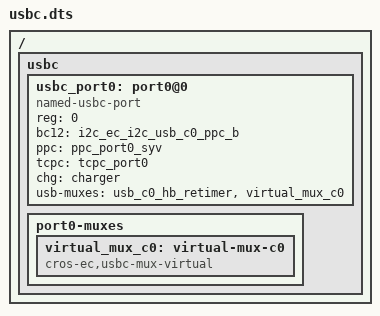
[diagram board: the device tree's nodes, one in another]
/* Copyright 2022 The ChromiumOS Authors
 * Use of this source code is governed by a BSD-style license that can be
 * found in the LICENSE file.
 */

/ {
	usbc {
		#address-cells = <1>;
		#size-cells = <0>;

		usbc_port0: port0@0 {
			compatible = "named-usbc-port";
			reg = <0>;
			bc12 = <&i2c_ec_i2c_usb_c0_ppc_b>;
			ppc = <&ppc_port0_syv>;
			tcpc = <&tcpc_port0>;
			chg = <&charger>;
			usb-muxes = <&usb_c0_hb_retimer &virtual_mux_c0>;
		};
		port0-muxes {
			virtual_mux_c0: virtual-mux-c0 {
				compatible = "cros-ec,usbc-mux-virtual";
			};
		};
	};
};
